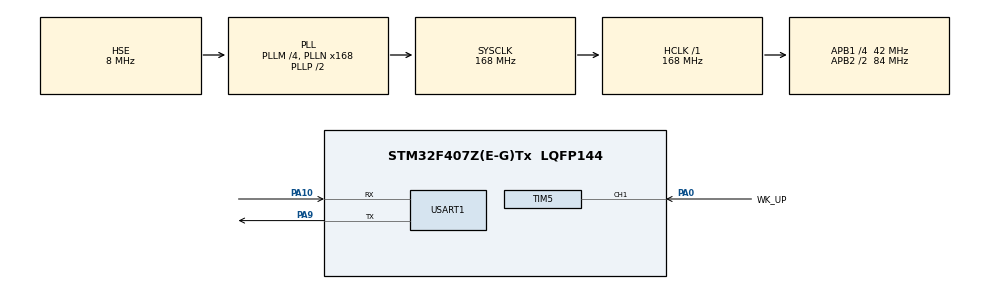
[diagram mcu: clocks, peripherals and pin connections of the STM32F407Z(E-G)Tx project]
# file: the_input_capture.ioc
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Mcu.Family=STM32F4
Mcu.Name=STM32F407Z(E-G)Tx
Mcu.Package=LQFP144
NVIC.PriorityGroup=NVIC_PRIORITYGROUP_4
NVIC.TIM5_IRQn=true\:0\:0\:false\:false\:true\:true\:true
PA0-WKUP.GPIO_Label=WK_UP
PA0-WKUP.GPIO_PuPd=GPIO_PULLDOWN
PA0-WKUP.GPIO_Speed=GPIO_SPEED_FREQ_LOW
PA0-WKUP.Signal=S_TIM5_CH1
PA10.Mode=Asynchronous
PA10.Signal=USART1_RX
PA9.Mode=Asynchronous
PA9.Signal=USART1_TX
PC14-OSC32_IN.Mode=LSE-External-Oscillator
PC14-OSC32_IN.Signal=RCC_OSC32_IN
PC15-OSC32_OUT.Mode=LSE-External-Oscillator
PC15-OSC32_OUT.Signal=RCC_OSC32_OUT
PH0-OSC_IN.Mode=HSE-External-Oscillator
PH0-OSC_IN.Signal=RCC_OSC_IN
PH1-OSC_OUT.Mode=HSE-External-Oscillator
PH1-OSC_OUT.Signal=RCC_OSC_OUT
ProjectManager.HeapSize=0x200
ProjectManager.StackSize=0x400
ProjectManager.TargetToolchain=MDK-ARM V5
RCC.48MHZClocksFreq_Value=84000000
RCC.AHBFreq_Value=168000000
RCC.APB1CLKDivider=RCC_HCLK_DIV4
RCC.APB1Freq_Value=42000000
RCC.APB1TimFreq_Value=84000000
RCC.APB2CLKDivider=RCC_HCLK_DIV2
RCC.APB2Freq_Value=84000000
RCC.APB2TimFreq_Value=168000000
RCC.CortexFreq_Value=168000000
RCC.HCLKFreq_Value=168000000
RCC.HSE_VALUE=8000000
RCC.HSI_VALUE=16000000
RCC.PLLM=4
RCC.PLLN=168
RCC.PLLSourceVirtual=RCC_PLLSOURCE_HSE
RCC.SYSCLKFreq_VALUE=168000000
RCC.SYSCLKSource=RCC_SYSCLKSOURCE_PLLCLK
RCC.VCOOutputFreq_Value=336000000
SH.S_TIM5_CH1.0=TIM5_CH1,Input_Capture1_from_TI1
TIM5.AutoReloadPreload=TIM_AUTORELOAD_PRELOAD_ENABLE
TIM5.Channel-Input_Capture1_from_TI1=TIM_CHANNEL_1
TIM5.ICFilter_CH1=8
TIM5.Period=0xFFFFFFFF
TIM5.Prescaler=84
USART1.VirtualMode=VM_ASYNC
board=custom

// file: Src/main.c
/* USER CODE BEGIN Header */
/**
  ******************************************************************************
  * @file           : main.c
  * @brief          : Main program body
  ******************************************************************************
  * @attention
  *
  * <h2><center>&copy; Copyright (c) 2019 STMicroelectronics.
  * All rights reserved.</center></h2>
  *
  * This software component is licensed by ST under BSD 3-Clause license,
  * the "License"; You may not use this file except in compliance with the
  * License. You may obtain a copy of the License at:
  *                        opensource.org/licenses/BSD-3-Clause
  *
  ******************************************************************************
  */
/* USER CODE END Header */

#include "main.h"
#include "tim.h"
#include "usart.h"
#include "gpio.h"

/* USER CODE BEGIN Includes */
#include <stdio.h>
/* USER CODE END Includes */

/* USER CODE BEGIN PM */
uint32_t capture_Buf[3] = {0};
uint8_t capture_Cnt = 0;
uint32_t high_time;
/* USER CODE END PM */

void SystemClock_Config(void);

/* USER CODE BEGIN 0 */
long long temp=0;
/* USER CODE END 0 */

int main(void)
{

  /* MCU Configuration--------------------------------------------------------*/

  /* Reset of all peripherals, Initializes the Flash interface and the Systick. */
  HAL_Init();

  /* Configure the system clock */
  SystemClock_Config();

  /* Initialize all configured peripherals */
  MX_GPIO_Init();
  MX_TIM5_Init();
  MX_USART1_UART_Init();
  /* USER CODE BEGIN 2 */
  HAL_TIM_IC_Start_IT(&htim5,TIM_CHANNEL_1);   //开启TIM5的捕获通道1，并且开启捕获中断
  __HAL_TIM_ENABLE_IT(&htim5,TIM_IT_UPDATE);   //使能更新中断

  /* USER CODE END 2 */

  /* Infinite loop */
  while (1)
  {

    /* USER CODE BEGIN 3 */
    if(TIM5CH1_CAPTURE_STA&0X80)        //成功捕获到了一次高电平
		{
			temp=TIM5CH1_CAPTURE_STA&0X3F;
			temp*=0XFFFFFFFF;		 	    //溢出时间总和
			temp+=TIM5CH1_CAPTURE_VAL;      //得到总的高电平时间
			printf("HIGH:%lld us\r\n",temp);//打印总的高点平时间
			TIM5CH1_CAPTURE_STA=0;          //开启下一次捕获
		}
  }
  /* USER CODE END 3 */
}

void SystemClock_Config(void)
{
  RCC_OscInitTypeDef RCC_OscInitStruct = {0};
  RCC_ClkInitTypeDef RCC_ClkInitStruct = {0};

  /** Configure the main internal regulator output voltage
  */
  __HAL_RCC_PWR_CLK_ENABLE();
  __HAL_PWR_VOLTAGESCALING_CONFIG(PWR_REGULATOR_VOLTAGE_SCALE1);
  /** Initializes the CPU, AHB and APB busses clocks
  */
  RCC_OscInitStruct.OscillatorType = RCC_OSCILLATORTYPE_HSE;
  RCC_OscInitStruct.HSEState = RCC_HSE_ON;
  RCC_OscInitStruct.PLL.PLLState = RCC_PLL_ON;
  RCC_OscInitStruct.PLL.PLLSource = RCC_PLLSOURCE_HSE;
  RCC_OscInitStruct.PLL.PLLM = 4;
  RCC_OscInitStruct.PLL.PLLN = 168;
  RCC_OscInitStruct.PLL.PLLP = RCC_PLLP_DIV2;
  RCC_OscInitStruct.PLL.PLLQ = 4;
  if (HAL_RCC_OscConfig(&RCC_OscInitStruct) != HAL_OK)
  {
    Error_Handler();
  }
  /** Initializes the CPU, AHB and APB busses clocks
  */
  RCC_ClkInitStruct.ClockType = RCC_CLOCKTYPE_HCLK|RCC_CLOCKTYPE_SYSCLK
                              |RCC_CLOCKTYPE_PCLK1|RCC_CLOCKTYPE_PCLK2;
  RCC_ClkInitStruct.SYSCLKSource = RCC_SYSCLKSOURCE_PLLCLK;
  RCC_ClkInitStruct.AHBCLKDivider = RCC_SYSCLK_DIV1;
  RCC_ClkInitStruct.APB1CLKDivider = RCC_HCLK_DIV4;
  RCC_ClkInitStruct.APB2CLKDivider = RCC_HCLK_DIV2;

  if (HAL_RCC_ClockConfig(&RCC_ClkInitStruct, FLASH_LATENCY_5) != HAL_OK)
  {
    Error_Handler();
  }
}

void Error_Handler(void)
{
}

/************************ (C) COPYRIGHT STMicroelectronics *****END OF FILE****/
